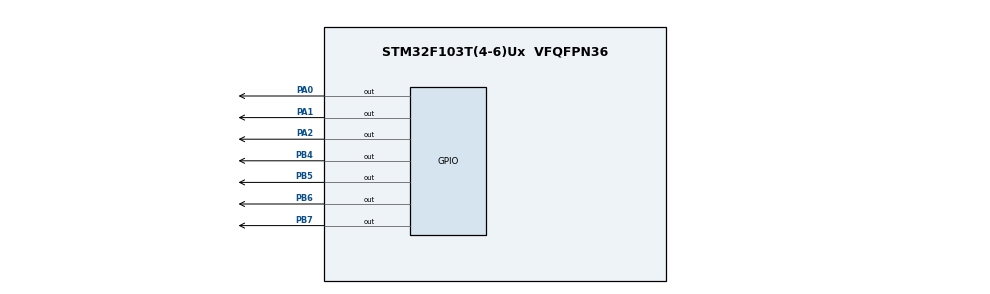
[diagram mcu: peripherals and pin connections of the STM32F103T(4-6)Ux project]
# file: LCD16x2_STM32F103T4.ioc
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Mcu.Family=STM32F1
Mcu.Name=STM32F103T(4-6)Ux
Mcu.Package=VFQFPN36
NVIC.PriorityGroup=NVIC_PRIORITYGROUP_4
PA0-WKUP.Signal=GPIO_Output
PA1.Signal=GPIO_Output
PA13.Mode=Serial_Wire
PA13.Signal=SYS_JTMS-SWDIO
PA14.Mode=Serial_Wire
PA14.Signal=SYS_JTCK-SWCLK
PA2.Signal=GPIO_Output
PB4.Signal=GPIO_Output
PB5.Signal=GPIO_Output
PB6.Signal=GPIO_Output
PB7.Signal=GPIO_Output
ProjectManager.HeapSize=0x200
ProjectManager.StackSize=0x400
ProjectManager.TargetToolchain=STM32CubeIDE
RCC.APB1Freq_Value=8000000
RCC.APB2Freq_Value=8000000
VP_RTC_VS_RTC_Activate.Mode=RTC_Enabled
VP_RTC_VS_RTC_Calendar.Mode=RTC_Calendar
board=custom

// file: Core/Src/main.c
/* USER CODE BEGIN Header */
/**
  ******************************************************************************
  * @file           : main.c
  * @brief          : Main program body
  ******************************************************************************
  * @attention
  *
  * <h2><center>&copy; Copyright (c) 2020 STMicroelectronics.
  * All rights reserved.</center></h2>
  *
  * This software component is licensed by ST under BSD 3-Clause license,
  * the "License"; You may not use this file except in compliance with the
  * License. You may obtain a copy of the License at:
  *                        opensource.org/licenses/BSD-3-Clause
  *
  ******************************************************************************
  */
/* USER CODE END Header */

#include "main.h"

/* USER CODE BEGIN Includes */
#include "LCD_HD44780.h"
/* USER CODE END Includes */

/* USER CODE BEGIN PTD */
RTC_TimeTypeDef sTime;
/* USER CODE END PTD */

RTC_HandleTypeDef hrtc;

void SystemClock_Config(void);
static void MX_GPIO_Init(void);
static void MX_RTC_Init(void);

int main(void)
{
  /* USER CODE BEGIN 1 */
	//uint32_t cont=0;
  /* USER CODE END 1 */

  /* MCU Configuration--------------------------------------------------------*/

  /* Reset of all peripherals, Initializes the Flash interface and the Systick. */
  HAL_Init();

  /* Configure the system clock */
  SystemClock_Config();

  /* Initialize all configured peripherals */
  MX_GPIO_Init();
  MX_RTC_Init();
  /* USER CODE BEGIN 2 */

  init_LCD_4bits();
  cmd_LCD(0x80);
 // write_string_LCD("Teste turbo!");

  /* USER CODE END 2 */

  /* Infinite loop */
  while (1)
  {
	  HAL_RTC_GetTime(&hrtc, &sTime, RTC_FORMAT_BIN);

	  write_time_LCD(sTime.Hours, sTime.Minutes, sTime.Seconds);

	  DESLOCA_CURSOR(0x80);
  }
}

void SystemClock_Config(void)
{
  RCC_OscInitTypeDef RCC_OscInitStruct = {0};
  RCC_ClkInitTypeDef RCC_ClkInitStruct = {0};
  RCC_PeriphCLKInitTypeDef PeriphClkInit = {0};

  /** Initializes the CPU, AHB and APB busses clocks
  */
  RCC_OscInitStruct.OscillatorType = RCC_OSCILLATORTYPE_HSI|RCC_OSCILLATORTYPE_LSI;
  RCC_OscInitStruct.HSIState = RCC_HSI_ON;
  RCC_OscInitStruct.HSICalibrationValue = RCC_HSICALIBRATION_DEFAULT;
  RCC_OscInitStruct.LSIState = RCC_LSI_ON;
  RCC_OscInitStruct.PLL.PLLState = RCC_PLL_NONE;
  if (HAL_RCC_OscConfig(&RCC_OscInitStruct) != HAL_OK)
  {
    Error_Handler();
  }
  /** Initializes the CPU, AHB and APB busses clocks
  */
  RCC_ClkInitStruct.ClockType = RCC_CLOCKTYPE_HCLK|RCC_CLOCKTYPE_SYSCLK
                              |RCC_CLOCKTYPE_PCLK1|RCC_CLOCKTYPE_PCLK2;
  RCC_ClkInitStruct.SYSCLKSource = RCC_SYSCLKSOURCE_HSI;
  RCC_ClkInitStruct.AHBCLKDivider = RCC_SYSCLK_DIV1;
  RCC_ClkInitStruct.APB1CLKDivider = RCC_HCLK_DIV1;
  RCC_ClkInitStruct.APB2CLKDivider = RCC_HCLK_DIV1;

  if (HAL_RCC_ClockConfig(&RCC_ClkInitStruct, FLASH_LATENCY_0) != HAL_OK)
  {
    Error_Handler();
  }
  PeriphClkInit.PeriphClockSelection = RCC_PERIPHCLK_RTC;
  PeriphClkInit.RTCClockSelection = RCC_RTCCLKSOURCE_LSI;
  if (HAL_RCCEx_PeriphCLKConfig(&PeriphClkInit) != HAL_OK)
  {
    Error_Handler();
  }
}

static void MX_RTC_Init(void)
{

  RTC_TimeTypeDef sTime = {0};
  RTC_DateTypeDef DateToUpdate = {0};

  /** Initialize RTC Only
  */
  hrtc.Instance = RTC;
  hrtc.Init.AsynchPrediv = RTC_AUTO_1_SECOND;
  hrtc.Init.OutPut = RTC_OUTPUTSOURCE_ALARM;
  if (HAL_RTC_Init(&hrtc) != HAL_OK)
  {
    Error_Handler();
  }

  /** Initialize RTC and set the Time and Date
  */
  sTime.Hours = 0x10;
  sTime.Minutes = 0x13;
  sTime.Seconds = 0x00;

  if (HAL_RTC_SetTime(&hrtc, &sTime, RTC_FORMAT_BCD) != HAL_OK)
  {
    Error_Handler();
  }
  DateToUpdate.WeekDay = RTC_WEEKDAY_MONDAY;
  DateToUpdate.Month = RTC_MONTH_JANUARY;
  DateToUpdate.Date = 0x1;
  DateToUpdate.Year = 0x0;

  if (HAL_RTC_SetDate(&hrtc, &DateToUpdate, RTC_FORMAT_BCD) != HAL_OK)
  {
    Error_Handler();
  }

}

static void MX_GPIO_Init(void)
{
  GPIO_InitTypeDef GPIO_InitStruct = {0};

  /* GPIO Ports Clock Enable */
  __HAL_RCC_GPIOA_CLK_ENABLE();
  __HAL_RCC_GPIOB_CLK_ENABLE();

  /*Configure GPIO pin Output Level */
  HAL_GPIO_WritePin(GPIOA, GPIO_PIN_0|GPIO_PIN_1|GPIO_PIN_2, GPIO_PIN_RESET);

  /*Configure GPIO pin Output Level */
  HAL_GPIO_WritePin(GPIOB, GPIO_PIN_4|GPIO_PIN_5|GPIO_PIN_6|GPIO_PIN_7, GPIO_PIN_RESET);

  /*Configure GPIO pins : PA0 PA1 PA2 */
  GPIO_InitStruct.Pin = GPIO_PIN_0|GPIO_PIN_1|GPIO_PIN_2;
  GPIO_InitStruct.Mode = GPIO_MODE_OUTPUT_PP;
  GPIO_InitStruct.Pull = GPIO_NOPULL;
  GPIO_InitStruct.Speed = GPIO_SPEED_FREQ_LOW;
  HAL_GPIO_Init(GPIOA, &GPIO_InitStruct);

  /*Configure GPIO pins : PB4 PB5 PB6 PB7 */
  GPIO_InitStruct.Pin = GPIO_PIN_4|GPIO_PIN_5|GPIO_PIN_6|GPIO_PIN_7;
  GPIO_InitStruct.Mode = GPIO_MODE_OUTPUT_PP;
  GPIO_InitStruct.Pull = GPIO_NOPULL;
  GPIO_InitStruct.Speed = GPIO_SPEED_FREQ_LOW;
  HAL_GPIO_Init(GPIOB, &GPIO_InitStruct);

}

void Error_Handler(void)
{
}

/************************ (C) COPYRIGHT STMicroelectronics *****END OF FILE****/
